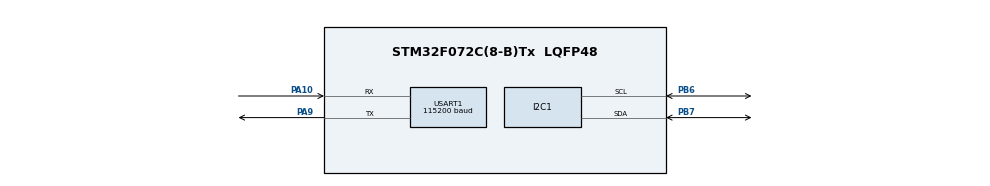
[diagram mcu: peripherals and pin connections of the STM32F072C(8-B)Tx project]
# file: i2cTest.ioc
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Mcu.Family=STM32F0
Mcu.Name=STM32F072C(8-B)Tx
Mcu.Package=LQFP48
NVIC.I2C1_IRQn=true\:0\:0\:false\:false\:true\:true\:true
NVIC.USART1_IRQn=true\:0\:0\:false\:false\:true\:true\:true
PA10.Mode=Asynchronous
PA10.Signal=USART1_RX
PA9.Mode=Asynchronous
PA9.Signal=USART1_TX
PB6.Mode=I2C
PB6.Signal=I2C1_SCL
PB7.Mode=I2C
PB7.Signal=I2C1_SDA
ProjectManager.HeapSize=0x200
ProjectManager.StackSize=0x400
ProjectManager.TargetToolchain=STM32CubeIDE
USART1.BaudRate=115200
USART1.VirtualMode-Asynchronous=VM_ASYNC
board=custom

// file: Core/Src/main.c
/* USER CODE BEGIN Header */
/**
  ******************************************************************************
  * @file           : main.c
  * @brief          : Main program body
  ******************************************************************************
  * @attention
  *
  * <h2><center>&copy; Copyright (c) 2021 STMicroelectronics.
  * All rights reserved.</center></h2>
  *
  * This software component is licensed by ST under BSD 3-Clause license,
  * the "License"; You may not use this file except in compliance with the
  * License. You may obtain a copy of the License at:
  *                        opensource.org/licenses/BSD-3-Clause
  *
  ******************************************************************************
  */
/* USER CODE END Header */
#include "main.h"
/* USER CODE BEGIN Includes */
//#include "VJI2C.h"
/* USER CODE END Includes */

I2C_HandleTypeDef hi2c1;

UART_HandleTypeDef huart1;

void SystemClock_Config(void);
static void MX_GPIO_Init(void);
static void MX_I2C1_Init(void);
static void MX_USART1_UART_Init(void);
/* USER CODE BEGIN PFP */

//#include "VJI2C.h"

/* USER CODE END PFP */

int main(void)
{
  /* USER CODE BEGIN 1 */
	//VJ_I2C stmI2cMaster;
  /* USER CODE END 1 */

  /* MCU Configuration--------------------------------------------------------*/

  /* Reset of all peripherals, Initializes the Flash interface and the Systick. */
  HAL_Init();

  /* Configure the system clock */
  SystemClock_Config();

  /* Initialize all configured peripherals */
  MX_GPIO_Init();
  MX_I2C1_Init();
  MX_USART1_UART_Init();

  /* Infinite loop */
  while (1)
  {

  }
}

void SystemClock_Config(void)
{
  RCC_OscInitTypeDef RCC_OscInitStruct = {0};
  RCC_ClkInitTypeDef RCC_ClkInitStruct = {0};
  RCC_PeriphCLKInitTypeDef PeriphClkInit = {0};

  /** Initializes the RCC Oscillators according to the specified parameters
  * in the RCC_OscInitTypeDef structure.
  */
  RCC_OscInitStruct.OscillatorType = RCC_OSCILLATORTYPE_HSI;
  RCC_OscInitStruct.HSIState = RCC_HSI_ON;
  RCC_OscInitStruct.HSICalibrationValue = RCC_HSICALIBRATION_DEFAULT;
  RCC_OscInitStruct.PLL.PLLState = RCC_PLL_NONE;
  if (HAL_RCC_OscConfig(&RCC_OscInitStruct) != HAL_OK)
  {
    Error_Handler();
  }
  /** Initializes the CPU, AHB and APB buses clocks
  */
  RCC_ClkInitStruct.ClockType = RCC_CLOCKTYPE_HCLK|RCC_CLOCKTYPE_SYSCLK
                              |RCC_CLOCKTYPE_PCLK1;
  RCC_ClkInitStruct.SYSCLKSource = RCC_SYSCLKSOURCE_HSI;
  RCC_ClkInitStruct.AHBCLKDivider = RCC_SYSCLK_DIV1;
  RCC_ClkInitStruct.APB1CLKDivider = RCC_HCLK_DIV1;

  if (HAL_RCC_ClockConfig(&RCC_ClkInitStruct, FLASH_LATENCY_0) != HAL_OK)
  {
    Error_Handler();
  }
  PeriphClkInit.PeriphClockSelection = RCC_PERIPHCLK_USART1|RCC_PERIPHCLK_I2C1;
  PeriphClkInit.Usart1ClockSelection = RCC_USART1CLKSOURCE_PCLK1;
  PeriphClkInit.I2c1ClockSelection = RCC_I2C1CLKSOURCE_HSI;
  if (HAL_RCCEx_PeriphCLKConfig(&PeriphClkInit) != HAL_OK)
  {
    Error_Handler();
  }
}

static void MX_I2C1_Init(void)
{

  hi2c1.Instance = I2C1;
  hi2c1.Init.Timing = 0x2000090E;
  hi2c1.Init.OwnAddress1 = 0;
  hi2c1.Init.AddressingMode = I2C_ADDRESSINGMODE_7BIT;
  hi2c1.Init.DualAddressMode = I2C_DUALADDRESS_DISABLE;
  hi2c1.Init.OwnAddress2 = 0;
  hi2c1.Init.OwnAddress2Masks = I2C_OA2_NOMASK;
  hi2c1.Init.GeneralCallMode = I2C_GENERALCALL_DISABLE;
  hi2c1.Init.NoStretchMode = I2C_NOSTRETCH_DISABLE;
  if (HAL_I2C_Init(&hi2c1) != HAL_OK)
  {
    Error_Handler();
  }
  /** Configure Analogue filter
  */
  if (HAL_I2CEx_ConfigAnalogFilter(&hi2c1, I2C_ANALOGFILTER_ENABLE) != HAL_OK)
  {
    Error_Handler();
  }
  /** Configure Digital filter
  */
  if (HAL_I2CEx_ConfigDigitalFilter(&hi2c1, 0) != HAL_OK)
  {
    Error_Handler();
  }

}

static void MX_USART1_UART_Init(void)
{

  huart1.Instance = USART1;
  huart1.Init.BaudRate = 115200;
  huart1.Init.WordLength = UART_WORDLENGTH_8B;
  huart1.Init.StopBits = UART_STOPBITS_1;
  huart1.Init.Parity = UART_PARITY_NONE;
  huart1.Init.Mode = UART_MODE_TX_RX;
  huart1.Init.HwFlowCtl = UART_HWCONTROL_NONE;
  huart1.Init.OverSampling = UART_OVERSAMPLING_16;
  huart1.Init.OneBitSampling = UART_ONE_BIT_SAMPLE_DISABLE;
  huart1.AdvancedInit.AdvFeatureInit = UART_ADVFEATURE_NO_INIT;
  if (HAL_UART_Init(&huart1) != HAL_OK)
  {
    Error_Handler();
  }

}

static void MX_GPIO_Init(void)
{

  /* GPIO Ports Clock Enable */
  __HAL_RCC_GPIOA_CLK_ENABLE();
  __HAL_RCC_GPIOB_CLK_ENABLE();

}

void Error_Handler(void)
{
  __disable_irq();
  while (1)
  {
  }
}

/************************ (C) COPYRIGHT STMicroelectronics *****END OF FILE****/
